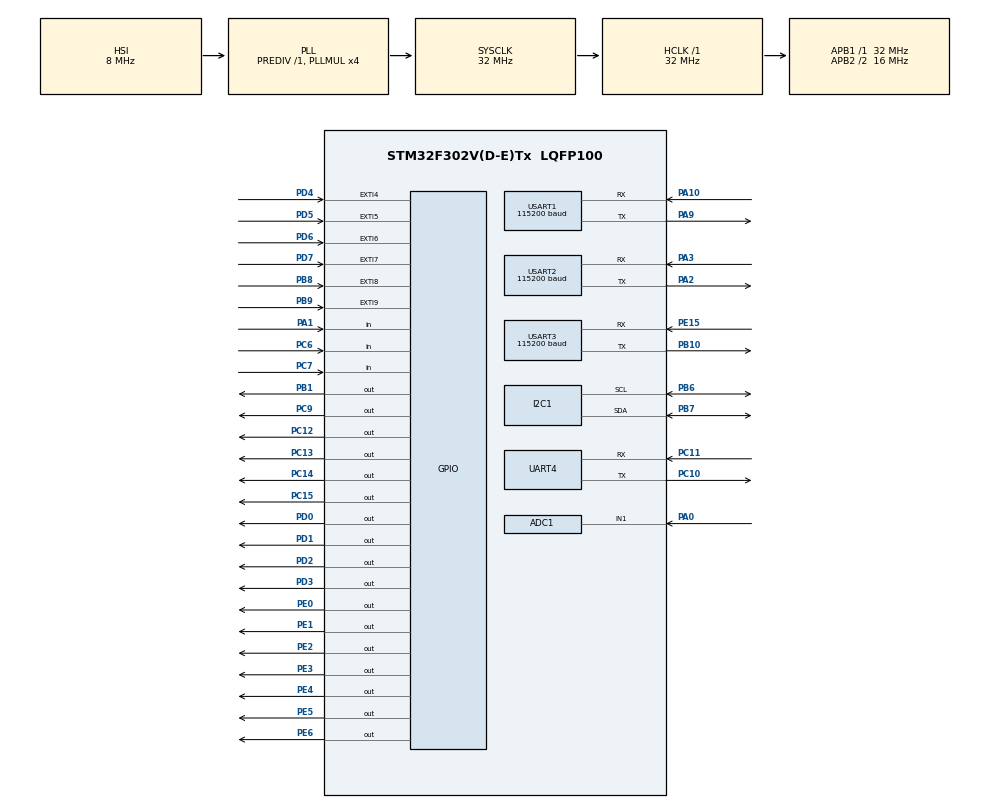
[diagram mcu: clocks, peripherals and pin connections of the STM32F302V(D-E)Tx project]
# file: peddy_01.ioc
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ADC1.Channel-47\#ChannelRegularConversion=ADC_CHANNEL_1
ADC1.ClockPrescaler=ADC_CLOCK_SYNC_PCLK_DIV4
ADC1.ContinuousConvMode=DISABLE
ADC1.DMAContinuousRequests=DISABLE
ADC1.DataAlign=ADC_DATAALIGN_RIGHT
ADC1.DiscontinuousConvMode=DISABLE
ADC1.EOCSelection=ADC_EOC_SINGLE_CONV
ADC1.EnableAnalogWatchDog1=false
ADC1.EnableAnalogWatchDog2=false
ADC1.EnableAnalogWatchDog3=false
ADC1.EnableInjectedConversion=ENABLE
ADC1.EnableRegularConversion=ENABLE
ADC1.ExternalTrigConv=ADC_SOFTWARE_START
ADC1.ExternalTrigConvEdge=ADC_EXTERNALTRIGCONVEDGE_NONE
ADC1.InjNumberOfConversion=0
ADC1.LowPowerAutoWait=DISABLE
ADC1.NbrOfConversion=1
ADC1.NbrOfConversionFlag=1
ADC1.Offset-47\#ChannelRegularConversion=0
ADC1.OffsetNumber-47\#ChannelRegularConversion=ADC_OFFSET_NONE
ADC1.Overrun=ADC_OVR_DATA_OVERWRITTEN
ADC1.Rank-47\#ChannelRegularConversion=1
ADC1.Resolution=ADC_RESOLUTION_12B
ADC1.SamplingTime-47\#ChannelRegularConversion=ADC_SAMPLETIME_181CYCLES_5
ADC1.ScanConvMode=ADC_SCAN_DISABLE
ADC1.master=1
Dma.Request0=UART4_RX
Dma.Request1=USART2_RX
Dma.UART4_RX.0.Direction=DMA_PERIPH_TO_MEMORY
Dma.UART4_RX.0.Instance=DMA2_Channel3
Dma.UART4_RX.0.MemDataAlignment=DMA_MDATAALIGN_BYTE
Dma.UART4_RX.0.MemInc=DMA_MINC_ENABLE
Dma.UART4_RX.0.Mode=DMA_NORMAL
Dma.UART4_RX.0.PeriphDataAlignment=DMA_PDATAALIGN_BYTE
Dma.UART4_RX.0.PeriphInc=DMA_PINC_DISABLE
Dma.UART4_RX.0.Priority=DMA_PRIORITY_LOW
Dma.USART2_RX.1.Direction=DMA_PERIPH_TO_MEMORY
Dma.USART2_RX.1.Instance=DMA1_Channel6
Dma.USART2_RX.1.MemDataAlignment=DMA_MDATAALIGN_BYTE
Dma.USART2_RX.1.MemInc=DMA_MINC_ENABLE
Dma.USART2_RX.1.Mode=DMA_NORMAL
Dma.USART2_RX.1.PeriphDataAlignment=DMA_PDATAALIGN_BYTE
Dma.USART2_RX.1.PeriphInc=DMA_PINC_DISABLE
Dma.USART2_RX.1.Priority=DMA_PRIORITY_LOW
Mcu.Family=STM32F3
Mcu.Name=STM32F302V(D-E)Tx
Mcu.Package=LQFP100
NVIC.DMA1_Channel6_IRQn=true\:0\:0\:false\:false\:true\:false\:true
NVIC.DMA2_Channel3_IRQn=true\:0\:0\:false\:false\:true\:false\:true
NVIC.EXTI4_IRQn=true\:0\:0\:false\:false\:true\:true\:true
NVIC.EXTI9_5_IRQn=true\:0\:0\:false\:false\:true\:true\:true
NVIC.I2C1_EV_IRQn=true\:0\:0\:false\:false\:true\:true\:true
NVIC.PriorityGroup=NVIC_PRIORITYGROUP_4
NVIC.TIM1_TRG_COM_TIM17_IRQn=true\:0\:0\:false\:false\:true\:true\:true
NVIC.TIM6_DAC_IRQn=true\:0\:0\:false\:false\:true\:true\:true
NVIC.UART4_IRQn=true\:0\:0\:false\:false\:true\:true\:true
NVIC.USART1_IRQn=true\:0\:0\:false\:false\:true\:true\:true
NVIC.USART2_IRQn=true\:0\:0\:false\:false\:true\:true\:true
PA0.Mode=IN1-Single-Ended
PA0.Signal=ADC1_IN1
PA1.Signal=GPIO_Input
PA10.Mode=Asynchronous
PA10.Signal=USART1_RX
PA13.Signal=SYS_JTMS-SWDIO
PA14.Signal=SYS_JTCK-SWCLK
PA2.Mode=Asynchronous
PA2.Signal=USART2_TX
PA3.Mode=Asynchronous
PA3.Signal=USART2_RX
PA9.Mode=Asynchronous
PA9.Signal=USART1_TX
PB1.GPIO_PuPd=GPIO_PULLUP
PB1.Signal=GPIO_Output
PB10.Mode=Asynchronous
PB10.Signal=USART3_TX
PB6.GPIO_FM6=SYSCFG_CFGR1_I2C_PB6_FMP
PB6.Mode=I2C
PB6.Signal=I2C1_SCL
PB7.GPIO_FM7=SYSCFG_CFGR1_I2C_PB7_FMP
PB7.Mode=I2C
PB7.Signal=I2C1_SDA
PB8.GPIO_ModeDefaultEXTI=GPIO_MODE_IT_FALLING
PB8.Signal=GPXTI8
PB9.GPIO_ModeDefaultEXTI=GPIO_MODE_IT_FALLING
PB9.Signal=GPXTI9
PC10.Mode=Asynchronous
PC10.Signal=UART4_TX
PC11.Mode=Asynchronous
PC11.Signal=UART4_RX
PC12.Signal=GPIO_Output
PC13.Signal=GPIO_Output
PC14-OSC32_IN.Signal=GPIO_Output
PC15-OSC32_OUT.Signal=GPIO_Output
PC5.Signal=ADC2_IN11
PC6.Signal=GPIO_Input
PC7.Signal=GPIO_Input
PC9.Signal=GPIO_Output
PD0.Signal=GPIO_Output
PD1.Signal=GPIO_Output
PD2.Signal=GPIO_Output
PD3.Signal=GPIO_Output
PD4.GPIO_ModeDefaultEXTI=GPIO_MODE_IT_RISING_FALLING
PD4.Signal=GPXTI4
PD5.GPIO_ModeDefaultEXTI=GPIO_MODE_IT_RISING_FALLING
PD5.Signal=GPXTI5
PD6.GPIO_ModeDefaultEXTI=GPIO_MODE_IT_RISING_FALLING
PD6.Signal=GPXTI6
PD7.GPIO_ModeDefaultEXTI=GPIO_MODE_IT_RISING_FALLING
PD7.Signal=GPXTI7
PE0.Signal=GPIO_Output
PE1.Signal=GPIO_Output
PE15.Mode=Asynchronous
PE15.Signal=USART3_RX
PE2.Signal=GPIO_Output
PE3.Signal=GPIO_Output
PE4.Signal=GPIO_Output
PE5.Signal=GPIO_Output
PE6.Signal=GPIO_Output
PF0-OSC_IN.Mode=HSE-External-Oscillator
PF0-OSC_IN.Signal=RCC_OSC_IN
PF1-OSC_OUT.Mode=HSE-External-Oscillator
PF1-OSC_OUT.Signal=RCC_OSC_OUT
ProjectManager.HeapSize=0x200
ProjectManager.StackSize=0x400
ProjectManager.TargetToolchain=EWARM V8.32
RCC.AHBFreq_Value=32000000
RCC.APB1Freq_Value=32000000
RCC.APB1TimFreq_Value=32000000
RCC.APB2CLKDivider=RCC_HCLK_DIV2
RCC.APB2Freq_Value=16000000
RCC.APB2TimFreq_Value=32000000
RCC.CortexFreq_Value=32000000
RCC.HCLKFreq_Value=32000000
RCC.HSE_VALUE=8000000
RCC.HSI_VALUE=8000000
RCC.LSE_VALUE=32768
RCC.PLLMUL=RCC_PLL_MUL4
RCC.SYSCLKFreq_VALUE=32000000
RCC.SYSCLKSourceVirtual=RCC_SYSCLKSOURCE_PLLCLK
RCC.USBFreq_Value=32000000
TIM17.Channel=TIM_CHANNEL_1
TIM17.Period=32-1
TIM17.Prescaler=10
TIM6.AutoReloadPreload=TIM_AUTORELOAD_PRELOAD_ENABLE
TIM6.Period=1
TIM6.Prescaler=5-1
TIM6.TIM_MasterOutputTrigger=TIM_TRGO_UPDATE
USART1.BaudRate=115200
USART1.VirtualMode-Asynchronous=VM_ASYNC
USART2.BaudRate=115200
USART2.VirtualMode-Asynchronous=VM_ASYNC
USART2.WordLength=WORDLENGTH_8B
USART3.BaudRate=115200
USART3.VirtualMode-Asynchronous=VM_ASYNC
VP_TIM17_VS_ClockSourceINT.Mode=Enable_Timer
VP_TIM17_VS_no_output1.Mode=Output Compare1 No Output
VP_TIM6_VS_ClockSourceINT.Mode=Enable_Timer
board=peddy_01

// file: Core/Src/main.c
/* USER CODE BEGIN Header */
/**
  ******************************************************************************
  * @file           : main.c
  * @brief          : Main program body
  ******************************************************************************
  * @attention
  *
  * <h2><center>&copy; Copyright (c) 2020 STMicroelectronics.
  * All rights reserved.</center></h2>
  *
  * This software component is licensed by ST under BSD 3-Clause license,
  * the "License"; You may not use this file except in compliance with the
  * License. You may obtain a copy of the License at:
  *                        opensource.org/licenses/BSD-3-Clause
  *
  ******************************************************************************
  */
/* USER CODE END Header */
#include "main.h"
#include "adc.h"
#include "dma.h"
#include "i2c.h"
#include "tim.h"
#include "usart.h"
#include "gpio.h"

void SystemClock_Config(void);

/* USER CODE BEGIN 0 */
int fputc(int ch,FILE *f)
{
  uint8_t temp[1]= {ch};
  // HAL_UART_Transmit(&huart1,temp,1,2);
  HAL_UART_Transmit(&huart4,temp,1,2);
  return (ch);
}
/* USER CODE END 0 */

int main(void)
{
  /* USER CODE BEGIN 1 */
//uint32_t ADC_VALUE=0;
//float ampar_value=0;
  /* USER CODE END 1 */

  /* MCU Configuration--------------------------------------------------------*/

  /* Reset of all peripherals, Initializes the Flash interface and the Systick. */
  HAL_Init();

  /* Configure the system clock */
  SystemClock_Config();

  /* Initialize all configured peripherals */
  MX_GPIO_Init();
  MX_DMA_Init();
  MX_ADC1_Init();
  MX_I2C1_Init();
  MX_TIM6_Init();
  MX_TIM17_Init();
  MX_USART2_UART_Init();
  MX_UART4_Init();
  MX_USART3_UART_Init();
  MX_USART1_UART_Init();
  /* USER CODE BEGIN 2 */
    Uart1_Rx_IT_Enable();
    Com1_RxInt_Enable();
    //init_SI7006();
    Start_Sonic();
    printf("hello");

  HAL_TIM_Base_Start_IT(&htim17);
  HAL_InitTick(TICK_INT_PRIORITY);
  /* USER CODE END 2 */

  /* Infinite loop */
  /* USER CODE BEGIN WHILE */
  while (1)
  {
    Logic_Sonic();
//   init_SI7006();

//   HAL_Delay(1);
    /* USER CODE END WHILE */

    /* USER CODE BEGIN 3 */

   //HAL_UART_Transmit(&huart2,"hello\r\n",sizeof("hello\r\n"),1000);
  }
  /* USER CODE END 3 */
}

void SystemClock_Config(void)
{
  RCC_OscInitTypeDef RCC_OscInitStruct = {0};
  RCC_ClkInitTypeDef RCC_ClkInitStruct = {0};
  RCC_PeriphCLKInitTypeDef PeriphClkInit = {0};

  /** Initializes the RCC Oscillators according to the specified parameters
  * in the RCC_OscInitTypeDef structure.
  */
  RCC_OscInitStruct.OscillatorType = RCC_OSCILLATORTYPE_HSI;
  RCC_OscInitStruct.HSIState = RCC_HSI_ON;
  RCC_OscInitStruct.HSICalibrationValue = RCC_HSICALIBRATION_DEFAULT;
  RCC_OscInitStruct.PLL.PLLState = RCC_PLL_ON;
  RCC_OscInitStruct.PLL.PLLSource = RCC_PLLSOURCE_HSI;
  RCC_OscInitStruct.PLL.PLLMUL = RCC_PLL_MUL4;
  RCC_OscInitStruct.PLL.PREDIV = RCC_PREDIV_DIV1;
  if (HAL_RCC_OscConfig(&RCC_OscInitStruct) != HAL_OK)
  {
    Error_Handler();
  }
  /** Initializes the CPU, AHB and APB buses clocks
  */
  RCC_ClkInitStruct.ClockType = RCC_CLOCKTYPE_HCLK|RCC_CLOCKTYPE_SYSCLK
                              |RCC_CLOCKTYPE_PCLK1|RCC_CLOCKTYPE_PCLK2;
  RCC_ClkInitStruct.SYSCLKSource = RCC_SYSCLKSOURCE_PLLCLK;
  RCC_ClkInitStruct.AHBCLKDivider = RCC_SYSCLK_DIV1;
  RCC_ClkInitStruct.APB1CLKDivider = RCC_HCLK_DIV1;
  RCC_ClkInitStruct.APB2CLKDivider = RCC_HCLK_DIV2;

  if (HAL_RCC_ClockConfig(&RCC_ClkInitStruct, FLASH_LATENCY_1) != HAL_OK)
  {
    Error_Handler();
  }
  PeriphClkInit.PeriphClockSelection = RCC_PERIPHCLK_USART1|RCC_PERIPHCLK_USART2
                              |RCC_PERIPHCLK_USART3|RCC_PERIPHCLK_UART4
                              |RCC_PERIPHCLK_I2C1|RCC_PERIPHCLK_TIM17;
  PeriphClkInit.Usart1ClockSelection = RCC_USART1CLKSOURCE_PCLK2;
  PeriphClkInit.Usart2ClockSelection = RCC_USART2CLKSOURCE_PCLK1;
  PeriphClkInit.Usart3ClockSelection = RCC_USART3CLKSOURCE_PCLK1;
  PeriphClkInit.Uart4ClockSelection = RCC_UART4CLKSOURCE_PCLK1;
  PeriphClkInit.I2c1ClockSelection = RCC_I2C1CLKSOURCE_HSI;
  PeriphClkInit.Tim17ClockSelection = RCC_TIM17CLK_HCLK;
  if (HAL_RCCEx_PeriphCLKConfig(&PeriphClkInit) != HAL_OK)
  {
    Error_Handler();
  }
}

void Error_Handler(void)
{
}

/************************ (C) COPYRIGHT STMicroelectronics *****END OF FILE****/
